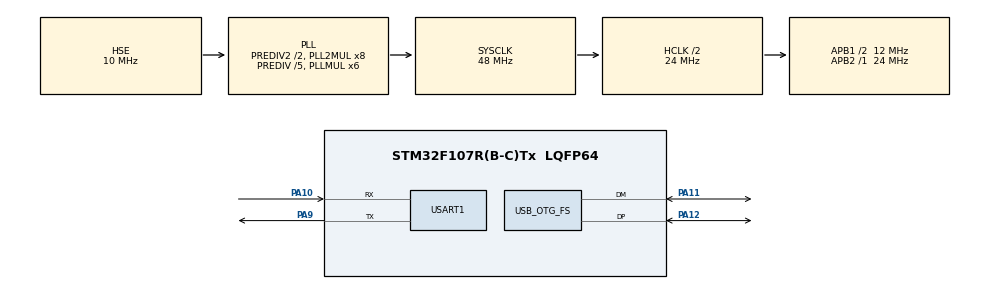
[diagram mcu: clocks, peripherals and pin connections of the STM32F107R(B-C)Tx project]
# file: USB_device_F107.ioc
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Mcu.Family=STM32F1
Mcu.Name=STM32F107R(B-C)Tx
Mcu.Package=LQFP64
NVIC.OTG_FS_IRQn=true\:0\:0\:false\:false\:true\:true\:true
NVIC.PriorityGroup=NVIC_PRIORITYGROUP_4
NVIC.USART1_IRQn=true\:0\:0\:false\:false\:true\:true\:true
PA10.Mode=Asynchronous
PA10.Signal=USART1_RX
PA11.Mode=Device_Only
PA11.Signal=USB_OTG_FS_DM
PA12.Mode=Device_Only
PA12.Signal=USB_OTG_FS_DP
PA9.Mode=Asynchronous
PA9.Signal=USART1_TX
PD0-OSC_IN.Mode=HSE-External-Oscillator
PD0-OSC_IN.Signal=RCC_OSC_IN
PD1-OSC_OUT.Mode=HSE-External-Oscillator
PD1-OSC_OUT.Signal=RCC_OSC_OUT
ProjectManager.HeapSize=0x200
ProjectManager.StackSize=0x400
ProjectManager.TargetToolchain=STM32CubeIDE
RCC.AHBCLKDivider=RCC_SYSCLK_DIV2
RCC.AHBFreq_Value=24000000
RCC.APB1CLKDivider=RCC_HCLK_DIV2
RCC.APB1Freq_Value=12000000
RCC.APB1TimFreq_Value=24000000
RCC.APB2Freq_Value=24000000
RCC.APB2TimFreq_Value=24000000
RCC.HCLKFreq_Value=24000000
RCC.HSEDivPLL=RCC_HSE_PREDIV_DIV5
RCC.HSE_VALUE=10000000
RCC.PLLMUL=RCC_PLL_MUL6
RCC.PLLSourceVirtual=RCC_PLLSOURCE_HSE
RCC.Prediv1Source=RCC_PREDIV1_SOURCE_PLL2
RCC.Prediv2=RCC_HSE_PREDIV2_DIV2
RCC.SYSCLKFreq_VALUE=48000000
RCC.SYSCLKSource=RCC_SYSCLKSOURCE_PLLCLK
RCC.USBFreq_Value=48000000
RCC.USBPrescaler=RCC_USBCLKSOURCE_PLL_DIV2
USART1.VirtualMode=VM_ASYNC
USB_DEVICE.CLASS_NAME_FS=CDC
USB_DEVICE.VirtualMode=Cdc
USB_DEVICE.VirtualModeFS=Cdc_FS
USB_OTG_FS.VirtualMode=Device_Only
VP_SYS_VS_ND.Mode=No_Debug
VP_USB_DEVICE_VS_USB_DEVICE_CDC_FS.Mode=CDC_FS
board=custom

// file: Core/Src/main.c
/* USER CODE BEGIN Header */
/**
  ******************************************************************************
  * @file           : main.c
  * @brief          : Main program body
  ******************************************************************************
  * @attention
  *
  * <h2><center>&copy; Copyright (c) 2020 STMicroelectronics.
  * All rights reserved.</center></h2>
  *
  * This software component is licensed by ST under BSD 3-Clause license,
  * the "License"; You may not use this file except in compliance with the
  * License. You may obtain a copy of the License at:
  *                        opensource.org/licenses/BSD-3-Clause
  *
  ******************************************************************************
  */
/* USER CODE END Header */
#include "main.h"
#include "usb_device.h"

UART_HandleTypeDef huart1;

void SystemClock_Config(void);
static void MX_GPIO_Init(void);
static void MX_USART1_UART_Init(void);

int main(void)
{

  /* MCU Configuration--------------------------------------------------------*/

  /* Reset of all peripherals, Initializes the Flash interface and the Systick. */
  HAL_Init();

  /* Configure the system clock */
  SystemClock_Config();

  /* Initialize all configured peripherals */
  MX_GPIO_Init();
  MX_USART1_UART_Init();
  MX_USB_DEVICE_Init();

  /* Infinite loop */
  /* USER CODE BEGIN WHILE */
  while (1)
  {
	/*
	HAL_GPIO_WritePin(GPIOA, GPIO_PIN_12, GPIO_PIN_RESET);
	HAL_GPIO_WritePin(GPIOA, GPIO_PIN_11, GPIO_PIN_RESET);
	HAL_Delay(2000);
	HAL_GPIO_WritePin(GPIOA, GPIO_PIN_12, GPIO_PIN_SET);
	HAL_GPIO_WritePin(GPIOA, GPIO_PIN_11, GPIO_PIN_SET);
	HAL_Delay(2000);
	*/
    /* USER CODE END WHILE */

  }
}

void SystemClock_Config(void)
{
  RCC_OscInitTypeDef RCC_OscInitStruct = {0};
  RCC_ClkInitTypeDef RCC_ClkInitStruct = {0};
  RCC_PeriphCLKInitTypeDef PeriphClkInit = {0};

  /** Initializes the RCC Oscillators according to the specified parameters
  * in the RCC_OscInitTypeDef structure.
  */
  RCC_OscInitStruct.OscillatorType = RCC_OSCILLATORTYPE_HSE;
  RCC_OscInitStruct.HSEState = RCC_HSE_ON;
  RCC_OscInitStruct.HSEPredivValue = RCC_HSE_PREDIV_DIV5;
  RCC_OscInitStruct.HSIState = RCC_HSI_ON;
  RCC_OscInitStruct.Prediv1Source = RCC_PREDIV1_SOURCE_PLL2;
  RCC_OscInitStruct.PLL.PLLState = RCC_PLL_ON;
  RCC_OscInitStruct.PLL.PLLSource = RCC_PLLSOURCE_HSE;
  RCC_OscInitStruct.PLL.PLLMUL = RCC_PLL_MUL6;
  RCC_OscInitStruct.PLL2.PLL2State = RCC_PLL2_ON;
  RCC_OscInitStruct.PLL2.PLL2MUL = RCC_PLL2_MUL8;
  RCC_OscInitStruct.PLL2.HSEPrediv2Value = RCC_HSE_PREDIV2_DIV2;
  if (HAL_RCC_OscConfig(&RCC_OscInitStruct) != HAL_OK)
  {
    Error_Handler();
  }
  /** Initializes the CPU, AHB and APB buses clocks
  */
  RCC_ClkInitStruct.ClockType = RCC_CLOCKTYPE_HCLK|RCC_CLOCKTYPE_SYSCLK
                              |RCC_CLOCKTYPE_PCLK1|RCC_CLOCKTYPE_PCLK2;
  RCC_ClkInitStruct.SYSCLKSource = RCC_SYSCLKSOURCE_PLLCLK;
  RCC_ClkInitStruct.AHBCLKDivider = RCC_SYSCLK_DIV2;
  RCC_ClkInitStruct.APB1CLKDivider = RCC_HCLK_DIV2;
  RCC_ClkInitStruct.APB2CLKDivider = RCC_HCLK_DIV1;

  if (HAL_RCC_ClockConfig(&RCC_ClkInitStruct, FLASH_LATENCY_1) != HAL_OK)
  {
    Error_Handler();
  }
  PeriphClkInit.PeriphClockSelection = RCC_PERIPHCLK_USB;
  PeriphClkInit.UsbClockSelection = RCC_USBCLKSOURCE_PLL_DIV2;
  if (HAL_RCCEx_PeriphCLKConfig(&PeriphClkInit) != HAL_OK)
  {
    Error_Handler();
  }
  /** Configure the Systick interrupt time
  */
  __HAL_RCC_PLLI2S_ENABLE();
}

static void MX_USART1_UART_Init(void)
{

  huart1.Instance = USART1;
  huart1.Init.BaudRate = 115200;
  huart1.Init.WordLength = UART_WORDLENGTH_8B;
  huart1.Init.StopBits = UART_STOPBITS_1;
  huart1.Init.Parity = UART_PARITY_NONE;
  huart1.Init.Mode = UART_MODE_TX_RX;
  huart1.Init.HwFlowCtl = UART_HWCONTROL_NONE;
  huart1.Init.OverSampling = UART_OVERSAMPLING_16;
  if (HAL_UART_Init(&huart1) != HAL_OK)
  {
    Error_Handler();
  }

}

static void MX_GPIO_Init(void)
{

  /* GPIO Ports Clock Enable */
  __HAL_RCC_GPIOD_CLK_ENABLE();
  __HAL_RCC_GPIOA_CLK_ENABLE();

}

void Error_Handler(void)
{
}

/************************ (C) COPYRIGHT STMicroelectronics *****END OF FILE****/
